AUTOSAR XML (schema 4-2-2)
package /STELLANTIS/EPT/ASWCs
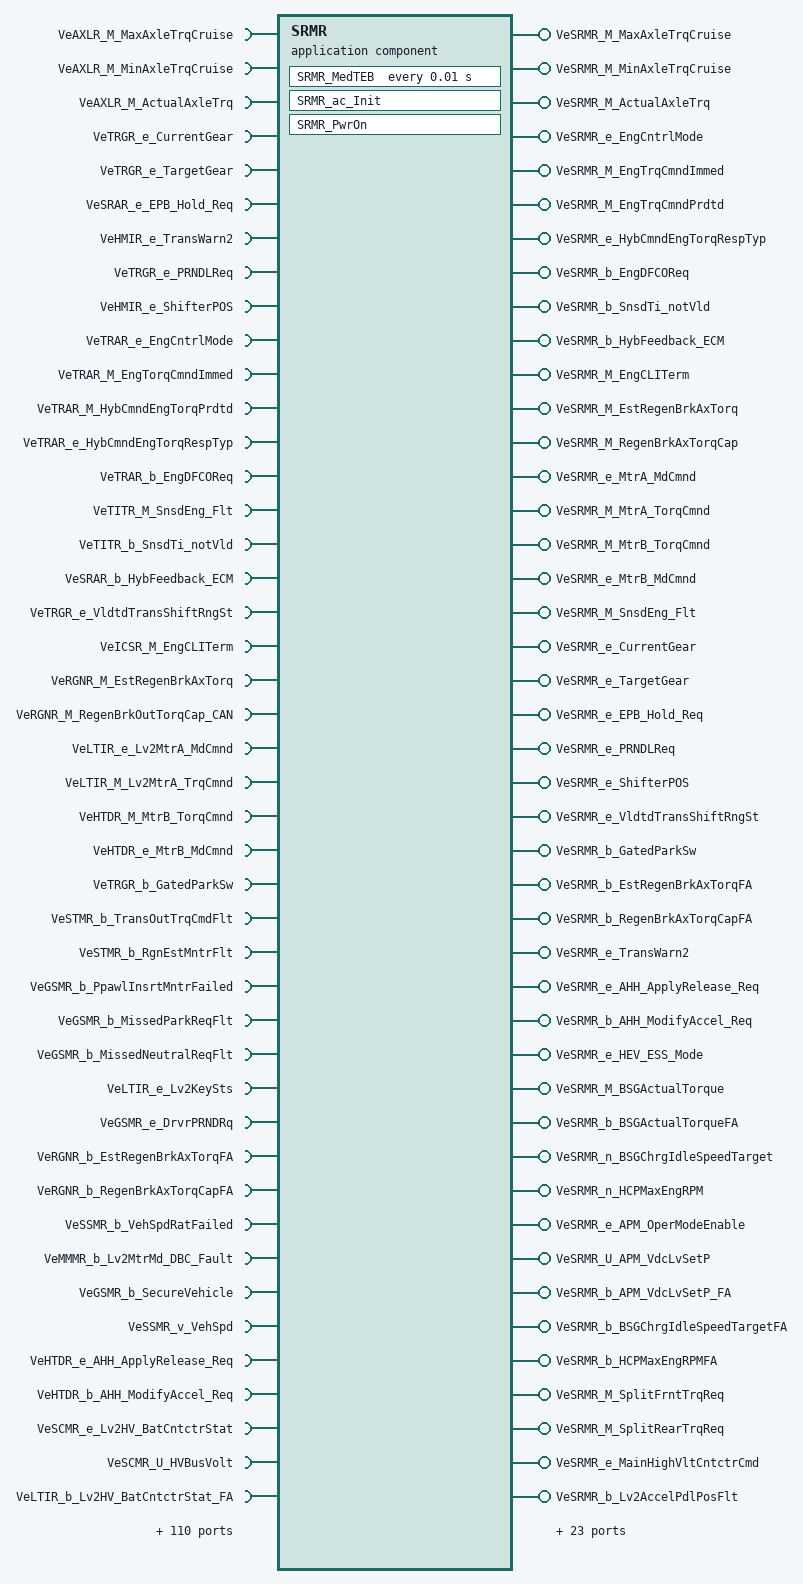
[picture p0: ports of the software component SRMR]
  application sw component type SRMR
    152 x require port:
      VeAXLR_M_MaxAxleTrqCruise: nonqueued-receiver-com-spec{data-element=Value, init-value=0}, required-interface=VeAXLR_M_MaxAxleTrqCruise
      VeAXLR_M_MinAxleTrqCruise: nonqueued-receiver-com-spec{data-element=Value, init-value=0}, required-interface=VeAXLR_M_MinAxleTrqCruise
      VeAXLR_M_ActualAxleTrq: nonqueued-receiver-com-spec{data-element=Value, init-value=0}, required-interface=VeAXLR_M_ActualAxleTrq
      VeTRGR_e_CurrentGear: nonqueued-receiver-com-spec{data-element=Value, init-value=0}, required-interface=VeTRGR_e_CurrentGear
      VeTRGR_e_TargetGear: nonqueued-receiver-com-spec{data-element=Value, init-value=0}, required-interface=VeTRGR_e_TargetGear
      VeSRAR_e_EPB_Hold_Req: nonqueued-receiver-com-spec{data-element=Value, init-value=CeTRGR_e_EPBReq_NA}, required-interface=VeSRAR_e_EPB_Hold_Req
      VeHMIR_e_TransWarn2: nonqueued-receiver-com-spec{data-element=Value, init-value=CeHMIR_e_Warn2_None}, required-interface=VeHMIR_e_TransWarn2
      VeTRGR_e_PRNDLReq: nonqueued-receiver-com-spec{data-element=Value, init-value=0}, required-interface=VeTRGR_e_PRNDLReq
      VeHMIR_e_ShifterPOS: nonqueued-receiver-com-spec{data-element=Value, init-value=CeHMIR_e_ShifterPosNoSelection}, required-interface=VeHMIR_e_ShifterPOS
      VeTRAR_e_EngCntrlMode: nonqueued-receiver-com-spec{data-element=Value, init-value=CeTRAR_e_TorqueMode}, required-interface=VeTRAR_e_EngCntrlMode
      VeTRAR_M_EngTorqCmndImmed: nonqueued-receiver-com-spec{data-element=Value, init-value=0}, required-interface=VeTRAR_M_EngTorqCmndImmed
      VeTRAR_M_HybCmndEngTorqPrdtd: nonqueued-receiver-com-spec{data-element=Value, init-value=0}, required-interface=VeTRAR_M_HybCmndEngTorqPrdtd
      VeTRAR_e_HybCmndEngTorqRespTyp: nonqueued-receiver-com-spec{data-element=Value, init-value=CeTRAR_e_Inactive}, required-interface=VeTRAR_e_HybCmndEngTorqRespTyp
      VeTRAR_b_EngDFCOReq: nonqueued-receiver-com-spec{data-element=Value, init-value=0}, required-interface=VeTRAR_b_EngDFCOReq
      VeTITR_M_SnsdEng_Flt: nonqueued-receiver-com-spec{data-element=Value, init-value=0}, required-interface=VeTITR_M_SnsdEng_Flt
      VeTITR_b_SnsdTi_notVld: nonqueued-receiver-com-spec{data-element=Value, init-value=0}, required-interface=VeTITR_b_SnsdTi_notVld
      VeSRAR_b_HybFeedback_ECM: nonqueued-receiver-com-spec{data-element=Value, init-value=0}, required-interface=VeSRAR_b_HybFeedback_ECM
      VeTRGR_e_VldtdTransShiftRngSt: nonqueued-receiver-com-spec{data-element=Value, init-value=CeTRGR_e_NoSelectionAvailable}, required-interface=VeTRGR_e_VldtdTransShiftRngSt
      VeICSR_M_EngCLITerm: nonqueued-receiver-com-spec{data-element=Value, init-value=0}, required-interface=VeICSR_M_EngCLITerm
      VeRGNR_M_EstRegenBrkAxTorq: nonqueued-receiver-com-spec{data-element=Value, init-value=0}, required-interface=VeRGNR_M_EstRegenBrkAxTorq
      VeRGNR_M_RegenBrkOutTorqCap_CAN: nonqueued-receiver-com-spec{data-element=Value, init-value=0}, required-interface=VeRGNR_M_RegenBrkOutTorqCap_CAN
      VeLTIR_e_Lv2MtrA_MdCmnd: nonqueued-receiver-com-spec{data-element=Value, init-value=CeHTDR_e_DsblNoSwitch}, required-interface=VeLTIR_e_Lv2MtrA_MdCmnd
      VeLTIR_M_Lv2MtrA_TrqCmnd: nonqueued-receiver-com-spec{data-element=Value, init-value=0}, required-interface=VeLTIR_M_Lv2MtrA_TrqCmnd
      VeHTDR_M_MtrB_TorqCmnd: nonqueued-receiver-com-spec{data-element=Value, init-value=0}, required-interface=VeHTDR_M_MtrB_TorqCmnd
      VeHTDR_e_MtrB_MdCmnd: nonqueued-receiver-com-spec{data-element=Value, init-value=CeHTDR_e_DsblNoSwitch}, required-interface=VeHTDR_e_MtrB_MdCmnd
      VeTRGR_b_GatedParkSw: nonqueued-receiver-com-spec{data-element=Value, init-value=0}, required-interface=VeTRGR_b_GatedParkSw
      VeSTMR_b_TransOutTrqCmdFlt: nonqueued-receiver-com-spec{data-element=Value, init-value=0}, required-interface=VeSTMR_b_TransOutTrqCmdFlt
      VeSTMR_b_RgnEstMntrFlt: nonqueued-receiver-com-spec{data-element=Value, init-value=0}, required-interface=VeSTMR_b_RgnEstMntrFlt
      VeGSMR_b_PpawlInsrtMntrFailed: nonqueued-receiver-com-spec{data-element=Value, init-value=0}, required-interface=VeGSMR_b_PpawlInsrtMntrFailed
      VeGSMR_b_MissedParkReqFlt: nonqueued-receiver-com-spec{data-element=Value, init-value=0}, required-interface=VeGSMR_b_MissedParkReqFlt
      VeGSMR_b_MissedNeutralReqFlt: nonqueued-receiver-com-spec{data-element=Value, init-value=0}, required-interface=VeGSMR_b_MissedNeutralReqFlt
      VeLTIR_e_Lv2KeySts: nonqueued-receiver-com-spec{data-element=Value, init-value=CeLTIR_e_IGN_LK}, required-interface=VeLTIR_e_Lv2KeySts
      VeGSMR_e_DrvrPRNDRq: nonqueued-receiver-com-spec{data-element=Value, init-value=CeGSMR_e_PRNDInit}, required-interface=VeGSMR_e_DrvrPRNDRq
      VeRGNR_b_EstRegenBrkAxTorqFA: nonqueued-receiver-com-spec{data-element=Value, init-value=0}, required-interface=VeRGNR_b_EstRegenBrkAxTorqFA
      VeRGNR_b_RegenBrkAxTorqCapFA: nonqueued-receiver-com-spec{data-element=Value, init-value=0}, required-interface=VeRGNR_b_RegenBrkAxTorqCapFA
      VeSSMR_b_VehSpdRatFailed: nonqueued-receiver-com-spec{data-element=Value, init-value=0}, required-interface=VeSSMR_b_VehSpdRatFailed
      VeMMMR_b_Lv2MtrMd_DBC_Fault: nonqueued-receiver-com-spec{data-element=Value, init-value=0}, required-interface=VeMMMR_b_Lv2MtrMd_DBC_Fault
      VeGSMR_b_SecureVehicle: nonqueued-receiver-com-spec{data-element=Value, init-value=0}, required-interface=VeGSMR_b_SecureVehicle
      VeSSMR_v_VehSpd: nonqueued-receiver-com-spec{data-element=Value, init-value=0}, required-interface=VeSSMR_v_VehSpd
      VeHTDR_e_AHH_ApplyRelease_Req: nonqueued-receiver-com-spec{data-element=Value, init-value=CeHTDR_e_AHH_Inactive}, required-interface=VeHTDR_e_AHH_ApplyRelease_Req
      VeHTDR_b_AHH_ModifyAccel_Req: nonqueued-receiver-com-spec{data-element=Value, init-value=0}, required-interface=VeHTDR_b_AHH_ModifyAccel_Req
      VeSCMR_e_Lv2HV_BatCntctrStat: nonqueued-receiver-com-spec{data-element=Value, init-value=0}, required-interface=VeSCMR_e_Lv2HV_BatCntctrStat
      VeSCMR_U_HVBusVolt: nonqueued-receiver-com-spec{data-element=Value, init-value=0}, required-interface=VeSCMR_U_HVBusVolt
      VeLTIR_b_Lv2HV_BatCntctrStat_FA: nonqueued-receiver-com-spec{data-element=Value, init-value=0}, required-interface=VeLTIR_b_Lv2HV_BatCntctrStat_FA
      VeSTMR_b_UnIntendedVehMovInNeutral: nonqueued-receiver-com-spec{data-element=Value, init-value=0}, required-interface=VeSTMR_b_UnIntendedVehMovInNeutral
      VeGSMR_b_ApplyEPB: nonqueued-receiver-com-spec{data-element=Value, init-value=0}, required-interface=VeGSMR_b_ApplyEPB
      VeASMR_e_Lv2EngStrtStpMd: nonqueued-receiver-com-spec{data-element=Value, init-value=0}, required-interface=VeASMR_e_Lv2EngStrtStpMd
      VeMTIR_M_MtrA_TorqAchieved: nonqueued-receiver-com-spec{data-element=Value, init-value=0}, required-interface=VeMTIR_M_MtrA_TorqAchieved
      VeMTIR_b_MtrA_TorqAchievedFA: nonqueued-receiver-com-spec{data-element=Value, init-value=0}, required-interface=VeMTIR_b_MtrA_TorqAchievedFA
      VeOHSR_n_IdleSpeed_Target: nonqueued-receiver-com-spec{data-element=Value, init-value=0}, required-interface=VeOHSR_n_IdleSpeed_Target
      VeSRAR_n_HCPMaxEngRPM: nonqueued-receiver-com-spec{data-element=Value, init-value=0}, required-interface=VeSRAR_n_HCPMaxEngRPM
      VeGENR_e_stModeReq: nonqueued-receiver-com-spec{data-element=Value, init-value=CeGENR_e_Default}, required-interface=VeGENR_e_stModeReq
      VeGENR_U_SetPVoltRq: nonqueued-receiver-com-spec{data-element=Value, init-value=0}, required-interface=VeGENR_U_SetPVoltRq
      VeGENR_b_SetPVoltRqFA: nonqueued-receiver-com-spec{data-element=Value, init-value=0}, required-interface=VeGENR_b_SetPVoltRqFA
      VeSCMR_M_Lv2MtrA_TrqAchieved: nonqueued-receiver-com-spec{data-element=Value, init-value=0}, required-interface=VeSCMR_M_Lv2MtrA_TrqAchieved
      VeLTIR_b_Lv2MtrA_TrqAchieved_FA: nonqueued-receiver-com-spec{data-element=Value, init-value=0}, required-interface=VeLTIR_b_Lv2MtrA_TrqAchieved_FA
      VeSCMR_Pct_Lv2HV_BatSOC: nonqueued-receiver-com-spec{data-element=Value, init-value=0}, required-interface=VeSCMR_Pct_Lv2HV_BatSOC
      VeLTIR_b_Lv2HV_BatSOC_FA: nonqueued-receiver-com-spec{data-element=Value, init-value=0}, required-interface=VeLTIR_b_Lv2HV_BatSOC_FA
      VeASMR_b_Lv2AutoStrtFA: nonqueued-receiver-com-spec{data-element=Value, init-value=0}, required-interface=VeASMR_b_Lv2AutoStrtFA
      VeASMR_b_Lv2AutoStpFA: nonqueued-receiver-com-spec{data-element=Value, init-value=0}, required-interface=VeASMR_b_Lv2AutoStpFA
      VeSTMR_b_EngTorqCmndMntrFlt: nonqueued-receiver-com-spec{data-element=Value, init-value=0}, required-interface=VeSTMR_b_EngTorqCmndMntrFlt
      VeSCMR_b_Lv2EVRDesVSetP_FA: nonqueued-receiver-com-spec{data-element=Value, init-value=0}, required-interface=VeSCMR_b_Lv2EVRDesVSetP_FA
      VeSCMR_U_Lv2EVRDesVSetP: nonqueued-receiver-com-spec{data-element=Value, init-value=0}, required-interface=VeSCMR_U_Lv2EVRDesVSetP
      VeGSMR_b_PpawlInsrtFailed: nonqueued-receiver-com-spec{data-element=Value, init-value=0}, required-interface=VeGSMR_b_PpawlInsrtFailed
      VeSTMR_b_OutTrq_MaxLimFail: nonqueued-receiver-com-spec{data-element=Value, init-value=0}, required-interface=VeSTMR_b_OutTrq_MaxLimFail
      VeAXLR_M_FrntAxlTrqEst: nonqueued-receiver-com-spec{data-element=Value, init-value=0}, required-interface=VeAXLR_M_FrntAxlTrqEst
      VeAXLR_M_RrAxlTrqEst: nonqueued-receiver-com-spec{data-element=Value, init-value=0}, required-interface=VeAXLR_M_RrAxlTrqEst
      VeSTMR_b_OutTrq_MinLimFail: nonqueued-receiver-com-spec{data-element=Value, init-value=0}, required-interface=VeSTMR_b_OutTrq_MinLimFail
      VeSTMR_b_P4TrqMntrFlt: nonqueued-receiver-com-spec{data-element=Value, init-value=0}, required-interface=VeSTMR_b_P4TrqMntrFlt
      VeESSR_e_EngStrtStpMd: nonqueued-receiver-com-spec{data-element=Value, init-value=CeESSR_e_Stop}, required-interface=VeESSR_e_EngStrtStpMd
      VeASMR_n_Lv2EngSpd: nonqueued-receiver-com-spec{data-element=Value, init-value=0}, required-interface=VeASMR_n_Lv2EngSpd
      VeSCMR_e_Lv2ESS_EngStateEE: nonqueued-receiver-com-spec{data-element=Value, init-value=0}, required-interface=VeSCMR_e_Lv2ESS_EngStateEE
      VeSCMR_b_SharedMemFlt: nonqueued-receiver-com-spec{data-element=Value, init-value=0}, required-interface=VeSCMR_b_SharedMemFlt
      VeSCMR_e_Lv2MtrA_InvrtrSts: nonqueued-receiver-com-spec{data-element=Value, init-value=0}, required-interface=VeSCMR_e_Lv2MtrA_InvrtrSts
      VeSCMR_b_Lv2HV_BatCntctrOpn: nonqueued-receiver-com-spec{data-element=Value, init-value=0}, required-interface=VeSCMR_b_Lv2HV_BatCntctrOpn
      VeSCMR_T_Lv2HV_BatModTempMax: nonqueued-receiver-com-spec{data-element=Value, init-value=0}, required-interface=VeSCMR_T_Lv2HV_BatModTempMax
      VeLTIR_b_Lv2HV_BatModTempMax_FA: nonqueued-receiver-com-spec{data-element=Value, init-value=0}, required-interface=VeLTIR_b_Lv2HV_BatModTempMax_FA
      VeLTIR_b_Lv2APM_HVBatVlt_FA: nonqueued-receiver-com-spec{data-element=Value, init-value=0}, required-interface=VeLTIR_b_Lv2APM_HVBatVlt_FA
      VeSCMR_b_BPCM_HVBatVltFA: nonqueued-receiver-com-spec{data-element=Value, init-value=0}, required-interface=VeSCMR_b_BPCM_HVBatVltFA
      VeSCMR_U_InvrtrA_HVBatVlt: nonqueued-receiver-com-spec{data-element=Value, init-value=0}, required-interface=VeSCMR_U_InvrtrA_HVBatVlt
      VeSCMR_U_BPCM_HVBatVlt: nonqueued-receiver-com-spec{data-element=Value, init-value=0}, required-interface=VeSCMR_U_BPCM_HVBatVlt
      VeSCMR_U_Lv2APM_HVBatVlt: nonqueued-receiver-com-spec{data-element=Value, init-value=0}, required-interface=VeSCMR_U_Lv2APM_HVBatVlt
      VeSCMR_e_Lv2APM_FailureType: nonqueued-receiver-com-spec{data-element=Value, init-value=0}, required-interface=VeSCMR_e_Lv2APM_FailureType
      VeSCMR_e_Lv2APM_FailureReason: nonqueued-receiver-com-spec{data-element=Value, init-value=0}, required-interface=VeSCMR_e_Lv2APM_FailureReason
      VeSCMR_b_Lv2HV_BatCntctrReq: nonqueued-receiver-com-spec{data-element=Value, init-value=0}, required-interface=VeSCMR_b_Lv2HV_BatCntctrReq
      VeHPMR_e_HighVltCntctrCntrl: nonqueued-receiver-com-spec{data-element=Value, init-value=CeHPMR_e_Open}, required-interface=VeHPMR_e_HighVltCntctrCntrl
      VePSMR_b_Lv2AccelPdlPosFlt: nonqueued-receiver-com-spec{data-element=Value, init-value=0}, required-interface=VePSMR_b_Lv2AccelPdlPosFlt
      VeLTIR_b_Lv2KeySts_FA: nonqueued-receiver-com-spec{data-element=Value, init-value=0}, required-interface=VeLTIR_b_Lv2KeySts_FA
      VeSCMR_b_ASC_Req: nonqueued-receiver-com-spec{data-element=Value, init-value=0}, required-interface=VeSCMR_b_ASC_Req
      VeSTMR_b_Allow_OpenBattCntctr: nonqueued-receiver-com-spec{data-element=Value, init-value=0}, required-interface=VeSTMR_b_Allow_OpenBattCntctr
      VeSTMR_b_P1fEstMntrFlt: nonqueued-receiver-com-spec{data-element=Value, init-value=0}, required-interface=VeSTMR_b_P1fEstMntrFlt
      VeSRAR_b_Popup_Msg15: nonqueued-receiver-com-spec{data-element=Value, init-value=0}, required-interface=VeSRAR_b_Popup_Msg15
      VeDTMR_b_Lv2_OPD_ON_FA: nonqueued-receiver-com-spec{data-element=Value, init-value=0}, required-interface=VeDTMR_b_Lv2_OPD_ON_FA
      VeSRAR_b_Popup_Msg9: nonqueued-receiver-com-spec{data-element=Value, init-value=0}, required-interface=VeSRAR_b_Popup_Msg9
      VeRGNR_b_AeCoastTorqDiffActv: nonqueued-receiver-com-spec{data-element=Value, init-value=0}, required-interface=VeRGNR_b_AeCoastTorqDiffActv
      VeDTRR_b_VehStndStillReq_OPD: nonqueued-receiver-com-spec{data-element=Value, init-value=0}, required-interface=VeDTRR_b_VehStndStillReq_OPD
      VeRGNR_M_AeCoastTorqDiff: nonqueued-receiver-com-spec{data-element=Value, init-value=0}, required-interface=VeRGNR_M_AeCoastTorqDiff
      VeSTMR_b_Lv2BattWeldFA: nonqueued-receiver-com-spec{data-element=Value, init-value=0}, required-interface=VeSTMR_b_Lv2BattWeldFA
      VeSTMR_b_P1fNotGeneratorMode: nonqueued-receiver-com-spec{data-element=Value, init-value=0}, required-interface=VeSTMR_b_P1fNotGeneratorMode
      VeSTMR_b_FrontAxleTrqEstMntrFlt: nonqueued-receiver-com-spec{data-element=Value, init-value=0}, required-interface=VeSTMR_b_FrontAxleTrqEstMntrFlt
      VeAXLR_b_ActualAxleTrqFA: nonqueued-receiver-com-spec{data-element=Value, init-value=0}, required-interface=VeAXLR_b_ActualAxleTrqFA
      VeSCMR_e_MSSBEV_Action: nonqueued-receiver-com-spec{data-element=Value, init-value=0}, required-interface=VeSCMR_e_MSSBEV_Action
      VeLTIR_e_Lv2BrkPdlStat: nonqueued-receiver-com-spec{data-element=Value, init-value=0}, required-interface=VeLTIR_e_Lv2BrkPdlStat
      VeLTIR_M_Lv2BrkTrq: nonqueued-receiver-com-spec{data-element=Value, init-value=0}, required-interface=VeLTIR_M_Lv2BrkTrq
      VePSMR_Pct_Lv2AccelPdlPos: nonqueued-receiver-com-spec{data-element=Value, init-value=0}, required-interface=VePSMR_Pct_Lv2AccelPdlPos
      VeSSMR_b_VehSpdFA: nonqueued-receiver-com-spec{data-element=Value, init-value=0}, required-interface=VeSSMR_b_VehSpdFA
      VeDTRR_b_DrvrIntndedAxleTrqRawFA: nonqueued-receiver-com-spec{data-element=Value, init-value=0}, required-interface=VeDTRR_b_DrvrIntndedAxleTrqRawFA
      VeAXLR_M_DrvrIntndedAxleTrq_Arb: nonqueued-receiver-com-spec{data-element=Value, init-value=0}, required-interface=VeAXLR_M_DrvrIntndedAxleTrq_Arb
      VeSTMR_b_FrntAxlTrqEstFA: nonqueued-receiver-com-spec{data-element=Value, init-value=0}, required-interface=VeSTMR_b_FrntAxlTrqEstFA
      VeSTMR_b_RrAxlTrqEstFA: nonqueued-receiver-com-spec{data-element=Value, init-value=0}, required-interface=VeSTMR_b_RrAxlTrqEstFA
      VeSTMR_b_DrvrIntndedAxleTrqFA: nonqueued-receiver-com-spec{data-element=Value, init-value=0}, required-interface=VeSTMR_b_DrvrIntndedAxleTrqFA
      VeSCMR_e_MSSBEV_HVEM_TargetSts: nonqueued-receiver-com-spec{data-element=Value, init-value=0}, required-interface=VeSCMR_e_MSSBEV_HVEM_TargetSts
      VeEMMR_b_Lv2APMStMode_FA: nonqueued-receiver-com-spec{data-element=Value, init-value=0}, required-interface=VeEMMR_b_Lv2APMStMode_FA
      VeSCMR_M_Lv2MtrB_MaxTrq: nonqueued-receiver-com-spec{data-element=Value, init-value=0}, required-interface=VeSCMR_M_Lv2MtrB_MaxTrq
      VeLTIR_b_Lv2MtrB_MaxTrq_FA: nonqueued-receiver-com-spec{data-element=Value, init-value=0}, required-interface=VeLTIR_b_Lv2MtrB_MaxTrq_FA
      VeSCMR_M_Lv2MtrB_MinTrq: nonqueued-receiver-com-spec{data-element=Value, init-value=0}, required-interface=VeSCMR_M_Lv2MtrB_MinTrq
      VeLTIR_b_Lv2MtrB_MinTrq_FA: nonqueued-receiver-com-spec{data-element=Value, init-value=0}, required-interface=VeLTIR_b_Lv2MtrB_MinTrq_FA
      VeSCMR_M_Lv2MtrA_MaxTrq: nonqueued-receiver-com-spec{data-element=Value, init-value=0}, required-interface=VeSCMR_M_Lv2MtrA_MaxTrq
      VeLTIR_b_Lv2MtrA_MaxTrq_FA: nonqueued-receiver-com-spec{data-element=Value, init-value=0}, required-interface=VeLTIR_b_Lv2MtrA_MaxTrq_FA
      VeSCMR_M_Lv2MtrA_MinTrq: nonqueued-receiver-com-spec{data-element=Value, init-value=0}, required-interface=VeSCMR_M_Lv2MtrA_MinTrq
      VeLTIR_b_Lv2MtrA_MinTrq_FA: nonqueued-receiver-com-spec{data-element=Value, init-value=0}, required-interface=VeLTIR_b_Lv2MtrA_MinTrq_FA
      VeSCMR_b_MSSBEV_Vbatt_mV_UV: nonqueued-receiver-com-spec{data-element=Value, init-value=0}, required-interface=VeSCMR_b_MSSBEV_Vbatt_mV_UV
      VeGENR_b_SrvcBattReChrgFlSts: nonqueued-receiver-com-spec{data-element=Value, init-value=0}, required-interface=VeGENR_b_SrvcBattReChrgFlSts
      VeLTIR_b_Lv2BrkPdlStatFlt: nonqueued-receiver-com-spec{data-element=Value, init-value=0}, required-interface=VeLTIR_b_Lv2BrkPdlStatFlt
      VeLTIR_b_Lv2BrkTrqFlt: nonqueued-receiver-com-spec{data-element=Value, init-value=0}, required-interface=VeLTIR_b_Lv2BrkTrqFlt
      VeSSMR_n_MtrBSpd: nonqueued-receiver-com-spec{data-element=Value, init-value=0}, required-interface=VeSSMR_n_MtrBSpd
      VeDTMR_b_DTRcmdFlt: nonqueued-receiver-com-spec{data-element=Value, init-value=0}, required-interface=VeDTMR_b_DTRcmdFlt
      VeSTMR_b_TrqSplit_OS_US: nonqueued-receiver-com-spec{data-element=Value, init-value=0}, required-interface=VeSTMR_b_TrqSplit_OS_US
      VeCANR_e_CanLocEnblStatus: nonqueued-receiver-com-spec{data-element=VeCANR_e_CanLocEnblStatus, init-value=CePWMD_e_LOC_Disable}, required-interface=VeCANR_e_CanLocEnblStatus
      VeSABR_b_SL2outBEV_VDAB_eAWD_SafActive: nonqueued-receiver-com-spec{data-element=Value, init-value=0}, required-interface=VeSABR_b_SL2outBEV_VDAB_eAWD_SafActive
      VeSABR_b_SL2outBEV_VDAB_WED_SafActive: nonqueued-receiver-com-spec{data-element=Value, init-value=0}, required-interface=VeSABR_b_SL2outBEV_VDAB_WED_SafActive
      VeSABR_b_SL2outBEV_VDAB_eLOCK_SafActive: nonqueued-receiver-com-spec{data-element=Value, init-value=0}, required-interface=VeSABR_b_SL2outBEV_VDAB_eLOCK_SafActive
      VeSABR_b_SL2outBEV_VDAB_eLSD_SafActive: nonqueued-receiver-com-spec{data-element=Value, init-value=0}, required-interface=VeSABR_b_SL2outBEV_VDAB_eLSD_SafActive
      VeGRAR_e_MSSBEV_Action: nonqueued-receiver-com-spec{data-element=Value, init-value=CeGRAR_e_NoLimitation}, required-interface=VeGRAR_e_MSSBEV_Action
      VeHPMR_b_MtrSystemActive: nonqueued-receiver-com-spec{data-element=Value, init-value=0}, required-interface=VeHPMR_b_MtrSystemActive
      VeGRAR_b_EngageParkBrk: nonqueued-receiver-com-spec{data-element=Value, init-value=0}, required-interface=VeGRAR_b_EngageParkBrk
      VeGRAR_b_DisableECoast: nonqueued-receiver-com-spec{data-element=Value, init-value=0}, required-interface=VeGRAR_b_DisableECoast
      VeGRAR_b_DisableOPD: nonqueued-receiver-com-spec{data-element=Value, init-value=0}, required-interface=VeGRAR_b_DisableOPD
      VePPCR_e_PPawl_HW_Request: nonqueued-receiver-com-spec{data-element=Value, init-value=CePPCR_e_Req_No_Req}, required-interface=VePPCR_e_PPawl_HW_Request
      VeSCMR_b_Lv2MtrAFlt_HV_CntctrOpnRq: nonqueued-receiver-com-spec{data-element=Value, init-value=0}, required-interface=VeSCMR_b_Lv2MtrAFlt_HV_CntctrOpnRq
      VeSCMR_b_Lv2MtrBFlt_HV_CntctrOpnRq: nonqueued-receiver-com-spec{data-element=Value, init-value=0}, required-interface=VeSCMR_b_Lv2MtrBFlt_HV_CntctrOpnRq
      VeGRAR_e_TotMtrTrqRmdlActn: nonqueued-receiver-com-spec{data-element=Value, init-value=CeGRAR_e_Normal}, required-interface=VeGRAR_e_TotMtrTrqRmdlActn
      VeGRAR_b_TotMtrTrqIncRampEnbl: nonqueued-receiver-com-spec{data-element=Value, init-value=0}, required-interface=VeGRAR_b_TotMtrTrqIncRampEnbl
      VeGRAR_b_Assign_RA_RIP_Ratio: nonqueued-receiver-com-spec{data-element=Value, init-value=0}, required-interface=VeGRAR_b_Assign_RA_RIP_Ratio
      VeGRAR_r_RA_RIP_Ratio: nonqueued-receiver-com-spec{data-element=Value, init-value=0}, required-interface=VeGRAR_r_RA_RIP_Ratio
      VeSCMR_b_Lv2MtrCFlt_HV_CntctrOpnRq: nonqueued-receiver-com-spec{data-element=Value, init-value=0}, required-interface=VeSCMR_b_Lv2MtrCFlt_HV_CntctrOpnRq
      VeRGNR_M_RegenBrkOutTorqCap_Frnt: nonqueued-receiver-com-spec{data-element=Value, init-value=0}, required-interface=VeRGNR_M_RegenBrkOutTorqCap_Frnt
      VeRGNR_M_RegenBrkOutTorqCap_Rear: nonqueued-receiver-com-spec{data-element=Value, init-value=0}, required-interface=VeRGNR_M_RegenBrkOutTorqCap_Rear
      VeGRAR_b_DisableRegenBrkTrq: nonqueued-receiver-com-spec{data-element=Value, init-value=0}, required-interface=VeGRAR_b_DisableRegenBrkTrq
      VePSMR_e_Lv2PVSMode: nonqueued-receiver-com-spec{data-element=Value, init-value=CePSMR_e_NO_Fault}, required-interface=VePSMR_e_Lv2PVSMode
      VeGRAR_e_ParkPawlReq: nonqueued-receiver-com-spec{data-element=Value, init-value=CeGRAR_e_PP_Normal}, required-interface=VeGRAR_e_ParkPawlReq
      VeGRAR_e_PRND_Req: nonqueued-receiver-com-spec{data-element=Value, init-value=CeGRAR_e_PRND_Normal}, required-interface=VeGRAR_e_PRND_Req
    67 x provide port:
      VeSRMR_M_MaxAxleTrqCruise: nonqueued-sender-com-spec{data-element=Value, init-value=0}, provided-interface=VeSRMR_M_MaxAxleTrqCruise
      VeSRMR_M_MinAxleTrqCruise: nonqueued-sender-com-spec{data-element=Value, init-value=0}, provided-interface=VeSRMR_M_MinAxleTrqCruise
      VeSRMR_M_ActualAxleTrq: nonqueued-sender-com-spec{data-element=Value, init-value=0}, provided-interface=VeSRMR_M_ActualAxleTrq
      VeSRMR_e_EngCntrlMode: nonqueued-sender-com-spec{data-element=Value, init-value=0}, provided-interface=VeSRMR_e_EngCntrlMode
      VeSRMR_M_EngTrqCmndImmed: nonqueued-sender-com-spec{data-element=Value, init-value=0}, provided-interface=VeSRMR_M_EngTrqCmndImmed
      VeSRMR_M_EngTrqCmndPrdtd: nonqueued-sender-com-spec{data-element=Value, init-value=0}, provided-interface=VeSRMR_M_EngTrqCmndPrdtd
      VeSRMR_e_HybCmndEngTorqRespTyp: nonqueued-sender-com-spec{data-element=Value, init-value=0}, provided-interface=VeSRMR_e_HybCmndEngTorqRespTyp
      VeSRMR_b_EngDFCOReq: nonqueued-sender-com-spec{data-element=Value, init-value=0}, provided-interface=VeSRMR_b_EngDFCOReq
      VeSRMR_b_SnsdTi_notVld: nonqueued-sender-com-spec{data-element=Value, init-value=0}, provided-interface=VeSRMR_b_SnsdTi_notVld
      VeSRMR_b_HybFeedback_ECM: nonqueued-sender-com-spec{data-element=Value, init-value=0}, provided-interface=VeSRMR_b_HybFeedback_ECM
      VeSRMR_M_EngCLITerm: nonqueued-sender-com-spec{data-element=Value, init-value=0}, provided-interface=VeSRMR_M_EngCLITerm
      VeSRMR_M_EstRegenBrkAxTorq: nonqueued-sender-com-spec{data-element=Value, init-value=0}, provided-interface=VeSRMR_M_EstRegenBrkAxTorq
      VeSRMR_M_RegenBrkAxTorqCap: nonqueued-sender-com-spec{data-element=Value, init-value=0}, provided-interface=VeSRMR_M_RegenBrkAxTorqCap
      VeSRMR_e_MtrA_MdCmnd: nonqueued-sender-com-spec{data-element=Value, init-value=CeHTDR_e_DsblNoSwitch}, provided-interface=VeSRMR_e_MtrA_MdCmnd
      VeSRMR_M_MtrA_TorqCmnd: nonqueued-sender-com-spec{data-element=Value, init-value=0}, provided-interface=VeSRMR_M_MtrA_TorqCmnd
      VeSRMR_M_MtrB_TorqCmnd: nonqueued-sender-com-spec{data-element=Value, init-value=0}, provided-interface=VeSRMR_M_MtrB_TorqCmnd
      VeSRMR_e_MtrB_MdCmnd: nonqueued-sender-com-spec{data-element=Value, init-value=CeHTDR_e_DsblNoSwitch}, provided-interface=VeSRMR_e_MtrB_MdCmnd
      VeSRMR_M_SnsdEng_Flt: nonqueued-sender-com-spec{data-element=Value, init-value=0}, provided-interface=VeSRMR_M_SnsdEng_Flt
      VeSRMR_e_CurrentGear: nonqueued-sender-com-spec{data-element=Value, init-value=0}, provided-interface=VeSRMR_e_CurrentGear
      VeSRMR_e_TargetGear: nonqueued-sender-com-spec{data-element=Value, init-value=0}, provided-interface=VeSRMR_e_TargetGear
      VeSRMR_e_EPB_Hold_Req: nonqueued-sender-com-spec{data-element=Value, init-value=0}, provided-interface=VeSRMR_e_EPB_Hold_Req
      VeSRMR_e_PRNDLReq: nonqueued-sender-com-spec{data-element=Value, init-value=0}, provided-interface=VeSRMR_e_PRNDLReq
      VeSRMR_e_ShifterPOS: nonqueued-sender-com-spec{data-element=Value, init-value=0}, provided-interface=VeSRMR_e_ShifterPOS
      VeSRMR_e_VldtdTransShiftRngSt: nonqueued-sender-com-spec{data-element=Value, init-value=CeTRGR_e_NoSelectionAvailable}, provided-interface=VeSRMR_e_VldtdTransShiftRngSt
      VeSRMR_b_GatedParkSw: nonqueued-sender-com-spec{data-element=Value, init-value=0}, provided-interface=VeSRMR_b_GatedParkSw
      VeSRMR_b_EstRegenBrkAxTorqFA: nonqueued-sender-com-spec{data-element=Value, init-value=0}, provided-interface=VeSRMR_b_EstRegenBrkAxTorqFA
      VeSRMR_b_RegenBrkAxTorqCapFA: nonqueued-sender-com-spec{data-element=Value, init-value=0}, provided-interface=VeSRMR_b_RegenBrkAxTorqCapFA
      VeSRMR_e_TransWarn2: nonqueued-sender-com-spec{data-element=Value, init-value=0}, provided-interface=VeSRMR_e_TransWarn2
      VeSRMR_e_AHH_ApplyRelease_Req: nonqueued-sender-com-spec{data-element=Value, init-value=0}, provided-interface=VeSRMR_e_AHH_ApplyRelease_Req
      VeSRMR_b_AHH_ModifyAccel_Req: nonqueued-sender-com-spec{data-element=Value, init-value=0}, provided-interface=VeSRMR_b_AHH_ModifyAccel_Req
      VeSRMR_e_HEV_ESS_Mode: nonqueued-sender-com-spec{data-element=Value, init-value=0}, provided-interface=VeSRMR_e_HEV_ESS_Mode
      VeSRMR_M_BSGActualTorque: nonqueued-sender-com-spec{data-element=Value, init-value=0}, provided-interface=VeSRMR_M_BSGActualTorque
      VeSRMR_b_BSGActualTorqueFA: nonqueued-sender-com-spec{data-element=Value, init-value=0}, provided-interface=VeSRMR_b_BSGActualTorqueFA
      VeSRMR_n_BSGChrgIdleSpeedTarget: nonqueued-sender-com-spec{data-element=Value, init-value=0}, provided-interface=VeSRMR_n_BSGChrgIdleSpeedTarget
      VeSRMR_n_HCPMaxEngRPM: nonqueued-sender-com-spec{data-element=Value, init-value=0}, provided-interface=VeSRMR_n_HCPMaxEngRPM
      VeSRMR_e_APM_OperModeEnable: nonqueued-sender-com-spec{data-element=Value, init-value=0}, provided-interface=VeSRMR_e_APM_OperModeEnable
      VeSRMR_U_APM_VdcLvSetP: nonqueued-sender-com-spec{data-element=Value, init-value=0}, provided-interface=VeSRMR_U_APM_VdcLvSetP
      VeSRMR_b_APM_VdcLvSetP_FA: nonqueued-sender-com-spec{data-element=Value, init-value=0}, provided-interface=VeSRMR_b_APM_VdcLvSetP_FA
      VeSRMR_b_BSGChrgIdleSpeedTargetFA: nonqueued-sender-com-spec{data-element=Value, init-value=0}, provided-interface=VeSRMR_b_BSGChrgIdleSpeedTargetFA
      VeSRMR_b_HCPMaxEngRPMFA: nonqueued-sender-com-spec{data-element=Value, init-value=0}, provided-interface=VeSRMR_b_HCPMaxEngRPMFA
      VeSRMR_M_SplitFrntTrqReq: nonqueued-sender-com-spec{data-element=Value, init-value=0}, provided-interface=VeSRMR_M_SplitFrntTrqReq
      VeSRMR_M_SplitRearTrqReq: nonqueued-sender-com-spec{data-element=Value, init-value=0}, provided-interface=VeSRMR_M_SplitRearTrqReq
      VeSRMR_e_MainHighVltCntctrCmd: nonqueued-sender-com-spec{data-element=Value, init-value=0}, provided-interface=VeSRMR_e_MainHighVltCntctrCmd
      VeSRMR_b_Lv2AccelPdlPosFlt: nonqueued-sender-com-spec{data-element=Value, init-value=0}, provided-interface=VeSRMR_b_Lv2AccelPdlPosFlt
      VeSRMR_Pct_Lv2AccelPdlPos: nonqueued-sender-com-spec{data-element=Value, init-value=0}, provided-interface=VeSRMR_Pct_Lv2AccelPdlPos
      VeSRMR_b_Popup_Msg15: nonqueued-sender-com-spec{data-element=Value, init-value=0}, provided-interface=VeSRMR_b_Popup_Msg15
      VeSRMR_b_Popup_Msg9: nonqueued-sender-com-spec{data-element=Value, init-value=0}, provided-interface=VeSRMR_b_Popup_Msg9
      VeSRMR_b_AeCoastTorqDiffActv: nonqueued-sender-com-spec{data-element=Value, init-value=0}, provided-interface=VeSRMR_b_AeCoastTorqDiffActv
      VeSRMR_M_AeCoastTorqDiff: nonqueued-sender-com-spec{data-element=Value, init-value=0}, provided-interface=VeSRMR_M_AeCoastTorqDiff
      VeSRMR_b_VehStndStillReq_OPD: nonqueued-sender-com-spec{data-element=Value, init-value=0}, provided-interface=VeSRMR_b_VehStndStillReq_OPD
      VeSRMR_b_ActualAxleTrqFA: nonqueued-sender-com-spec{data-element=Value, init-value=0}, provided-interface=VeSRMR_b_ActualAxleTrqFA
      VeSRMR_M_DrvrIntndedAxleTrq: nonqueued-sender-com-spec{data-element=Value, init-value=0}, provided-interface=VeSRMR_M_DrvrIntndedAxleTrq
      VeSRMR_b_DrvrIntndedAxleTrqFA: nonqueued-sender-com-spec{data-element=Value, init-value=0}, provided-interface=VeSRMR_b_DrvrIntndedAxleTrqFA
      VeSRMR_e_stModeReq: nonqueued-sender-com-spec{data-element=Value, init-value=0}, provided-interface=VeSRMR_e_stModeReq
      VeSRMR_b_CrashDischarge: nonqueued-sender-com-spec{data-element=Value, init-value=0}, provided-interface=VeSRMR_b_CrashDischarge
      VeSRMR_b_SrvcBattReChrgFlSts: nonqueued-sender-com-spec{data-element=Value, init-value=0}, provided-interface=VeSRMR_b_SrvcBattReChrgFlSts
      VeSRMR_e_GRAR_eAWD_TargetSts: nonqueued-sender-com-spec{data-element=Value, init-value=CeSRMR_e_TargetSts_DiagOff}, provided-interface=VeSRMR_e_GRAR_eAWD_TargetSts
      VeSRMR_e_GRAR_WED_TargetSts: nonqueued-sender-com-spec{data-element=Value, init-value=CeSRMR_e_TargetSts_DiagOff}, provided-interface=VeSRMR_e_GRAR_WED_TargetSts
      VeSRMR_e_GRAR_eLOCK_TargetSts: nonqueued-sender-com-spec{data-element=Value, init-value=CeSRMR_e_TargetSts_DiagOff}, provided-interface=VeSRMR_e_GRAR_eLOCK_TargetSts
      VeSRMR_e_GRAR_eLSD_TargetSts: nonqueued-sender-com-spec{data-element=Value, init-value=CeSRMR_e_TargetSts_DiagOff}, provided-interface=VeSRMR_e_GRAR_eLSD_TargetSts
      VeSRMR_e_LimitationMd: nonqueued-sender-com-spec{data-element=Value, init-value=CeSRMR_e_NoLimitation}, provided-interface=VeSRMR_e_LimitationMd
      VeSRMR_b_MtrMdVldtnFltErr: nonqueued-sender-com-spec{data-element=Value, init-value=0}, provided-interface=VeSRMR_b_MtrMdVldtnFltErr
      VeSRMR_v_VehSpd: nonqueued-sender-com-spec{data-element=Value, init-value=0}, provided-interface=VeSRMR_v_VehSpd
      VeSRMR_b_VehSpdFA: nonqueued-sender-com-spec{data-element=Value, init-value=0}, provided-interface=VeSRMR_b_VehSpdFA
      VeSRMR_e_PPawl_Request: nonqueued-sender-com-spec{data-element=Value, init-value=CePPCR_e_Req_No_Req}, provided-interface=VeSRMR_e_PPawl_Request
      VeSRMR_M_RegenBrkAxTorqCapFrnt: nonqueued-sender-com-spec{data-element=Value, init-value=0}, provided-interface=VeSRMR_M_RegenBrkAxTorqCapFrnt
      VeSRMR_M_RegenBrkAxTorqCapRear: nonqueued-sender-com-spec{data-element=Value, init-value=0}, provided-interface=VeSRMR_M_RegenBrkAxTorqCapRear
    require port SRMR_MedTEB_StartCheckpoint: client-com-spec=CheckpointReached, required-interface=WdgM_LocalSupervision
    require port SRMR_MedTEB_StopCheckpoint: client-com-spec=CheckpointReached, required-interface=WdgM_LocalSupervision
    behavior IB_SRMR: data-type-mapping=msADTtoIDTMapping, handle-termination-and-restart=NO-SUPPORT, included-data-type-set=data-type=TeSRMR_e_GRAR_Action
      timing event Event_MedTEB: start-on-event=SRMR_MedTEB, period=0.01
      init event Event_SRMR_ac_Init: start-on-event=SRMR_ac_Init
      init event Event_PwrOn: start-on-event=SRMR_PwrOn
      runnable SRMR_ac_Init
        data-send-points:
          9 x access:
            OUT_VeSRMR_e_MtrA_MdCmnd_Value: accessed-variable=VeSRMR_e_MtrA_MdCmnd.Value
            OUT_VeSRMR_e_MtrB_MdCmnd_Value: accessed-variable=VeSRMR_e_MtrB_MdCmnd.Value
            OUT_VeSRMR_e_VldtdTransShiftRngSt_Value: accessed-variable=VeSRMR_e_VldtdTransShiftRngSt.Value
            OUT_VeSRMR_e_GRAR_eAWD_TargetSts_Value: accessed-variable=VeSRMR_e_GRAR_eAWD_TargetSts.Value
            OUT_VeSRMR_e_GRAR_WED_TargetSts_Value: accessed-variable=VeSRMR_e_GRAR_WED_TargetSts.Value
            OUT_VeSRMR_e_GRAR_eLOCK_TargetSts_Value: accessed-variable=VeSRMR_e_GRAR_eLOCK_TargetSts.Value
            OUT_VeSRMR_e_GRAR_eLSD_TargetSts_Value: accessed-variable=VeSRMR_e_GRAR_eLSD_TargetSts.Value
            OUT_VeSRMR_e_LimitationMd_Value: accessed-variable=VeSRMR_e_LimitationMd.Value
            OUT_VeSRMR_e_PPawl_Request_Value: accessed-variable=VeSRMR_e_PPawl_Request.Value
      runnable SRMR_MedTEB
        data-receive-point-by-arguments:
          152 x access:
            IN_VeASMR_b_Lv2AutoStpFA_Value: accessed-variable=VeASMR_b_Lv2AutoStpFA.Value
            IN_VeASMR_b_Lv2AutoStrtFA_Value: accessed-variable=VeASMR_b_Lv2AutoStrtFA.Value
            IN_VeASMR_e_Lv2EngStrtStpMd_Value: accessed-variable=VeASMR_e_Lv2EngStrtStpMd.Value
            IN_VeASMR_n_Lv2EngSpd_Value: accessed-variable=VeASMR_n_Lv2EngSpd.Value
            IN_VeAXLR_M_ActualAxleTrq_Value: accessed-variable=VeAXLR_M_ActualAxleTrq.Value
            IN_VeAXLR_M_DrvrIntndedAxleTrq_Arb_Value: accessed-variable=VeAXLR_M_DrvrIntndedAxleTrq_Arb.Value
            IN_VeAXLR_M_FrntAxlTrqEst_Value: accessed-variable=VeAXLR_M_FrntAxlTrqEst.Value
            IN_VeAXLR_M_MaxAxleTrqCruise_Value: accessed-variable=VeAXLR_M_MaxAxleTrqCruise.Value
            IN_VeAXLR_M_MinAxleTrqCruise_Value: accessed-variable=VeAXLR_M_MinAxleTrqCruise.Value
            IN_VeAXLR_M_RrAxlTrqEst_Value: accessed-variable=VeAXLR_M_RrAxlTrqEst.Value
            IN_VeAXLR_b_ActualAxleTrqFA_Value: accessed-variable=VeAXLR_b_ActualAxleTrqFA.Value
            IN_VeCANR_e_CanLocEnblStatus_VeCANR_e_CanLocEnblStatus: accessed-variable=VeCANR_e_CanLocEnblStatus.VeCANR_e_CanLocEnblStatus
            IN_VeDTMR_b_DTRcmdFlt_Value: accessed-variable=VeDTMR_b_DTRcmdFlt.Value
            IN_VeDTMR_b_Lv2_OPD_ON_FA_Value: accessed-variable=VeDTMR_b_Lv2_OPD_ON_FA.Value
            IN_VeDTRR_b_DrvrIntndedAxleTrqRawFA_Value: accessed-variable=VeDTRR_b_DrvrIntndedAxleTrqRawFA.Value
            IN_VeDTRR_b_VehStndStillReq_OPD_Value: accessed-variable=VeDTRR_b_VehStndStillReq_OPD.Value
            IN_VeEMMR_b_Lv2APMStMode_FA_Value: accessed-variable=VeEMMR_b_Lv2APMStMode_FA.Value
            IN_VeESSR_e_EngStrtStpMd_Value: accessed-variable=VeESSR_e_EngStrtStpMd.Value
            IN_VeGENR_U_SetPVoltRq_Value: accessed-variable=VeGENR_U_SetPVoltRq.Value
            IN_VeGENR_b_SetPVoltRqFA_Value: accessed-variable=VeGENR_b_SetPVoltRqFA.Value
            IN_VeGENR_b_SrvcBattReChrgFlSts_Value: accessed-variable=VeGENR_b_SrvcBattReChrgFlSts.Value
            IN_VeGENR_e_stModeReq_Value: accessed-variable=VeGENR_e_stModeReq.Value
            IN_VeGRAR_b_Assign_RA_RIP_Ratio_Value: accessed-variable=VeGRAR_b_Assign_RA_RIP_Ratio.Value
            IN_VeGRAR_b_DisableECoast_Value: accessed-variable=VeGRAR_b_DisableECoast.Value
            IN_VeGRAR_b_DisableOPD_Value: accessed-variable=VeGRAR_b_DisableOPD.Value
            IN_VeGRAR_b_DisableRegenBrkTrq_Value: accessed-variable=VeGRAR_b_DisableRegenBrkTrq.Value
            IN_VeGRAR_b_EngageParkBrk_Value: accessed-variable=VeGRAR_b_EngageParkBrk.Value
            IN_VeGRAR_b_TotMtrTrqIncRampEnbl_Value: accessed-variable=VeGRAR_b_TotMtrTrqIncRampEnbl.Value
            IN_VeGRAR_e_MSSBEV_Action_Value: accessed-variable=VeGRAR_e_MSSBEV_Action.Value
            IN_VeGRAR_e_PRND_Req_Value: accessed-variable=VeGRAR_e_PRND_Req.Value
            IN_VeGRAR_e_ParkPawlReq_Value: accessed-variable=VeGRAR_e_ParkPawlReq.Value
            IN_VeGRAR_e_TotMtrTrqRmdlActn_Value: accessed-variable=VeGRAR_e_TotMtrTrqRmdlActn.Value
            IN_VeGRAR_r_RA_RIP_Ratio_Value: accessed-variable=VeGRAR_r_RA_RIP_Ratio.Value
            IN_VeGSMR_b_ApplyEPB_Value: accessed-variable=VeGSMR_b_ApplyEPB.Value
            IN_VeGSMR_b_MissedNeutralReqFlt_Value: accessed-variable=VeGSMR_b_MissedNeutralReqFlt.Value
            IN_VeGSMR_b_MissedParkReqFlt_Value: accessed-variable=VeGSMR_b_MissedParkReqFlt.Value
            IN_VeGSMR_b_PpawlInsrtFailed_Value: accessed-variable=VeGSMR_b_PpawlInsrtFailed.Value
            IN_VeGSMR_b_PpawlInsrtMntrFailed_Value: accessed-variable=VeGSMR_b_PpawlInsrtMntrFailed.Value
            IN_VeGSMR_b_SecureVehicle_Value: accessed-variable=VeGSMR_b_SecureVehicle.Value
            IN_VeGSMR_e_DrvrPRNDRq_Value: accessed-variable=VeGSMR_e_DrvrPRNDRq.Value
            IN_VeHMIR_e_ShifterPOS_Value: accessed-variable=VeHMIR_e_ShifterPOS.Value
            IN_VeHMIR_e_TransWarn2_Value: accessed-variable=VeHMIR_e_TransWarn2.Value
            IN_VeHPMR_b_MtrSystemActive_Value: accessed-variable=VeHPMR_b_MtrSystemActive.Value
            IN_VeHPMR_e_HighVltCntctrCntrl_Value: accessed-variable=VeHPMR_e_HighVltCntctrCntrl.Value
            IN_VeHTDR_M_MtrB_TorqCmnd_Value: accessed-variable=VeHTDR_M_MtrB_TorqCmnd.Value
            IN_VeHTDR_b_AHH_ModifyAccel_Req_Value: accessed-variable=VeHTDR_b_AHH_ModifyAccel_Req.Value
            IN_VeHTDR_e_AHH_ApplyRelease_Req_Value: accessed-variable=VeHTDR_e_AHH_ApplyRelease_Req.Value
            IN_VeHTDR_e_MtrB_MdCmnd_Value: accessed-variable=VeHTDR_e_MtrB_MdCmnd.Value
            IN_VeICSR_M_EngCLITerm_Value: accessed-variable=VeICSR_M_EngCLITerm.Value
            IN_VeLTIR_M_Lv2BrkTrq_Value: accessed-variable=VeLTIR_M_Lv2BrkTrq.Value
            IN_VeLTIR_M_Lv2MtrA_TrqCmnd_Value: accessed-variable=VeLTIR_M_Lv2MtrA_TrqCmnd.Value
            IN_VeLTIR_b_Lv2APM_HVBatVlt_FA_Value: accessed-variable=VeLTIR_b_Lv2APM_HVBatVlt_FA.Value
            IN_VeLTIR_b_Lv2BrkPdlStatFlt_Value: accessed-variable=VeLTIR_b_Lv2BrkPdlStatFlt.Value
            IN_VeLTIR_b_Lv2BrkTrqFlt_Value: accessed-variable=VeLTIR_b_Lv2BrkTrqFlt.Value
            IN_VeLTIR_b_Lv2HV_BatCntctrStat_FA_Value: accessed-variable=VeLTIR_b_Lv2HV_BatCntctrStat_FA.Value
            IN_VeLTIR_b_Lv2HV_BatModTempMax_FA_Value: accessed-variable=VeLTIR_b_Lv2HV_BatModTempMax_FA.Value
            IN_VeLTIR_b_Lv2HV_BatSOC_FA_Value: accessed-variable=VeLTIR_b_Lv2HV_BatSOC_FA.Value
            IN_VeLTIR_b_Lv2KeySts_FA_Value: accessed-variable=VeLTIR_b_Lv2KeySts_FA.Value
            IN_VeLTIR_b_Lv2MtrA_MaxTrq_FA_Value: accessed-variable=VeLTIR_b_Lv2MtrA_MaxTrq_FA.Value
            IN_VeLTIR_b_Lv2MtrA_MinTrq_FA_Value: accessed-variable=VeLTIR_b_Lv2MtrA_MinTrq_FA.Value
            IN_VeLTIR_b_Lv2MtrA_TrqAchieved_FA_Value: accessed-variable=VeLTIR_b_Lv2MtrA_TrqAchieved_FA.Value
            IN_VeLTIR_b_Lv2MtrB_MaxTrq_FA_Value: accessed-variable=VeLTIR_b_Lv2MtrB_MaxTrq_FA.Value
            IN_VeLTIR_b_Lv2MtrB_MinTrq_FA_Value: accessed-variable=VeLTIR_b_Lv2MtrB_MinTrq_FA.Value
            IN_VeLTIR_e_Lv2BrkPdlStat_Value: accessed-variable=VeLTIR_e_Lv2BrkPdlStat.Value
            IN_VeLTIR_e_Lv2KeySts_Value: accessed-variable=VeLTIR_e_Lv2KeySts.Value
            IN_VeLTIR_e_Lv2MtrA_MdCmnd_Value: accessed-variable=VeLTIR_e_Lv2MtrA_MdCmnd.Value
            IN_VeMMMR_b_Lv2MtrMd_DBC_Fault_Value: accessed-variable=VeMMMR_b_Lv2MtrMd_DBC_Fault.Value
            IN_VeMTIR_M_MtrA_TorqAchieved_Value: accessed-variable=VeMTIR_M_MtrA_TorqAchieved.Value
            IN_VeMTIR_b_MtrA_TorqAchievedFA_Value: accessed-variable=VeMTIR_b_MtrA_TorqAchievedFA.Value
            IN_VeOHSR_n_IdleSpeed_Target_Value: accessed-variable=VeOHSR_n_IdleSpeed_Target.Value
            IN_VePPCR_e_PPawl_HW_Request_Value: accessed-variable=VePPCR_e_PPawl_HW_Request.Value
            IN_VePSMR_Pct_Lv2AccelPdlPos_Value: accessed-variable=VePSMR_Pct_Lv2AccelPdlPos.Value
            IN_VePSMR_b_Lv2AccelPdlPosFlt_Value: accessed-variable=VePSMR_b_Lv2AccelPdlPosFlt.Value
            IN_VePSMR_e_Lv2PVSMode_Value: accessed-variable=VePSMR_e_Lv2PVSMode.Value
            IN_VeRGNR_M_AeCoastTorqDiff_Value: accessed-variable=VeRGNR_M_AeCoastTorqDiff.Value
            IN_VeRGNR_M_EstRegenBrkAxTorq_Value: accessed-variable=VeRGNR_M_EstRegenBrkAxTorq.Value
            IN_VeRGNR_M_RegenBrkOutTorqCap_CAN_Value: accessed-variable=VeRGNR_M_RegenBrkOutTorqCap_CAN.Value
            IN_VeRGNR_M_RegenBrkOutTorqCap_Frnt_Value: accessed-variable=VeRGNR_M_RegenBrkOutTorqCap_Frnt.Value
            IN_VeRGNR_M_RegenBrkOutTorqCap_Rear_Value: accessed-variable=VeRGNR_M_RegenBrkOutTorqCap_Rear.Value
            IN_VeRGNR_b_AeCoastTorqDiffActv_Value: accessed-variable=VeRGNR_b_AeCoastTorqDiffActv.Value
            IN_VeRGNR_b_EstRegenBrkAxTorqFA_Value: accessed-variable=VeRGNR_b_EstRegenBrkAxTorqFA.Value
            IN_VeRGNR_b_RegenBrkAxTorqCapFA_Value: accessed-variable=VeRGNR_b_RegenBrkAxTorqCapFA.Value
            IN_VeSABR_b_SL2outBEV_VDAB_WED_SafActive_Value: accessed-variable=VeSABR_b_SL2outBEV_VDAB_WED_SafActive.Value
            IN_VeSABR_b_SL2outBEV_VDAB_eAWD_SafActive_Value: accessed-variable=VeSABR_b_SL2outBEV_VDAB_eAWD_SafActive.Value
            IN_VeSABR_b_SL2outBEV_VDAB_eLOCK_SafActive_Value: accessed-variable=VeSABR_b_SL2outBEV_VDAB_eLOCK_SafActive.Value
            IN_VeSABR_b_SL2outBEV_VDAB_eLSD_SafActive_Value: accessed-variable=VeSABR_b_SL2outBEV_VDAB_eLSD_SafActive.Value
            IN_VeSCMR_M_Lv2MtrA_MaxTrq_Value: accessed-variable=VeSCMR_M_Lv2MtrA_MaxTrq.Value
            IN_VeSCMR_M_Lv2MtrA_MinTrq_Value: accessed-variable=VeSCMR_M_Lv2MtrA_MinTrq.Value
            IN_VeSCMR_M_Lv2MtrA_TrqAchieved_Value: accessed-variable=VeSCMR_M_Lv2MtrA_TrqAchieved.Value
            IN_VeSCMR_M_Lv2MtrB_MaxTrq_Value: accessed-variable=VeSCMR_M_Lv2MtrB_MaxTrq.Value
            IN_VeSCMR_M_Lv2MtrB_MinTrq_Value: accessed-variable=VeSCMR_M_Lv2MtrB_MinTrq.Value
            IN_VeSCMR_Pct_Lv2HV_BatSOC_Value: accessed-variable=VeSCMR_Pct_Lv2HV_BatSOC.Value
            IN_VeSCMR_T_Lv2HV_BatModTempMax_Value: accessed-variable=VeSCMR_T_Lv2HV_BatModTempMax.Value
            IN_VeSCMR_U_BPCM_HVBatVlt_Value: accessed-variable=VeSCMR_U_BPCM_HVBatVlt.Value
            IN_VeSCMR_U_HVBusVolt_Value: accessed-variable=VeSCMR_U_HVBusVolt.Value
            IN_VeSCMR_U_InvrtrA_HVBatVlt_Value: accessed-variable=VeSCMR_U_InvrtrA_HVBatVlt.Value
            IN_VeSCMR_U_Lv2APM_HVBatVlt_Value: accessed-variable=VeSCMR_U_Lv2APM_HVBatVlt.Value
            IN_VeSCMR_U_Lv2EVRDesVSetP_Value: accessed-variable=VeSCMR_U_Lv2EVRDesVSetP.Value
            IN_VeSCMR_b_ASC_Req_Value: accessed-variable=VeSCMR_b_ASC_Req.Value
            IN_VeSCMR_b_BPCM_HVBatVltFA_Value: accessed-variable=VeSCMR_b_BPCM_HVBatVltFA.Value
            IN_VeSCMR_b_Lv2EVRDesVSetP_FA_Value: accessed-variable=VeSCMR_b_Lv2EVRDesVSetP_FA.Value
            IN_VeSCMR_b_Lv2HV_BatCntctrOpn_Value: accessed-variable=VeSCMR_b_Lv2HV_BatCntctrOpn.Value
            IN_VeSCMR_b_Lv2HV_BatCntctrReq_Value: accessed-variable=VeSCMR_b_Lv2HV_BatCntctrReq.Value
            IN_VeSCMR_b_Lv2MtrAFlt_HV_CntctrOpnRq_Value: accessed-variable=VeSCMR_b_Lv2MtrAFlt_HV_CntctrOpnRq.Value
            IN_VeSCMR_b_Lv2MtrBFlt_HV_CntctrOpnRq_Value: accessed-variable=VeSCMR_b_Lv2MtrBFlt_HV_CntctrOpnRq.Value
            IN_VeSCMR_b_Lv2MtrCFlt_HV_CntctrOpnRq_Value: accessed-variable=VeSCMR_b_Lv2MtrCFlt_HV_CntctrOpnRq.Value
            IN_VeSCMR_b_MSSBEV_Vbatt_mV_UV_Value: accessed-variable=VeSCMR_b_MSSBEV_Vbatt_mV_UV.Value
            IN_VeSCMR_b_SharedMemFlt_Value: accessed-variable=VeSCMR_b_SharedMemFlt.Value
            IN_VeSCMR_e_Lv2APM_FailureReason_Value: accessed-variable=VeSCMR_e_Lv2APM_FailureReason.Value
            IN_VeSCMR_e_Lv2APM_FailureType_Value: accessed-variable=VeSCMR_e_Lv2APM_FailureType.Value
            IN_VeSCMR_e_Lv2ESS_EngStateEE_Value: accessed-variable=VeSCMR_e_Lv2ESS_EngStateEE.Value
            IN_VeSCMR_e_Lv2HV_BatCntctrStat_Value: accessed-variable=VeSCMR_e_Lv2HV_BatCntctrStat.Value
            IN_VeSCMR_e_Lv2MtrA_InvrtrSts_Value: accessed-variable=VeSCMR_e_Lv2MtrA_InvrtrSts.Value
            IN_VeSCMR_e_MSSBEV_Action_Value: accessed-variable=VeSCMR_e_MSSBEV_Action.Value
            IN_VeSCMR_e_MSSBEV_HVEM_TargetSts_Value: accessed-variable=VeSCMR_e_MSSBEV_HVEM_TargetSts.Value
            IN_VeSRAR_b_HybFeedback_ECM_Value: accessed-variable=VeSRAR_b_HybFeedback_ECM.Value
            IN_VeSRAR_b_Popup_Msg15_Value: accessed-variable=VeSRAR_b_Popup_Msg15.Value
            IN_VeSRAR_b_Popup_Msg9_Value: accessed-variable=VeSRAR_b_Popup_Msg9.Value
            IN_VeSRAR_e_EPB_Hold_Req_Value: accessed-variable=VeSRAR_e_EPB_Hold_Req.Value
            IN_VeSRAR_n_HCPMaxEngRPM_Value: accessed-variable=VeSRAR_n_HCPMaxEngRPM.Value
            IN_VeSSMR_b_VehSpdFA_Value: accessed-variable=VeSSMR_b_VehSpdFA.Value
            IN_VeSSMR_b_VehSpdRatFailed_Value: accessed-variable=VeSSMR_b_VehSpdRatFailed.Value
            IN_VeSSMR_n_MtrBSpd_Value: accessed-variable=VeSSMR_n_MtrBSpd.Value
            IN_VeSSMR_v_VehSpd_Value: accessed-variable=VeSSMR_v_VehSpd.Value
            IN_VeSTMR_b_Allow_OpenBattCntctr_Value: accessed-variable=VeSTMR_b_Allow_OpenBattCntctr.Value
            IN_VeSTMR_b_DrvrIntndedAxleTrqFA_Value: accessed-variable=VeSTMR_b_DrvrIntndedAxleTrqFA.Value
            IN_VeSTMR_b_EngTorqCmndMntrFlt_Value: accessed-variable=VeSTMR_b_EngTorqCmndMntrFlt.Value
            IN_VeSTMR_b_FrntAxlTrqEstFA_Value: accessed-variable=VeSTMR_b_FrntAxlTrqEstFA.Value
            IN_VeSTMR_b_FrontAxleTrqEstMntrFlt_Value: accessed-variable=VeSTMR_b_FrontAxleTrqEstMntrFlt.Value
            IN_VeSTMR_b_Lv2BattWeldFA_Value: accessed-variable=VeSTMR_b_Lv2BattWeldFA.Value
            IN_VeSTMR_b_OutTrq_MaxLimFail_Value: accessed-variable=VeSTMR_b_OutTrq_MaxLimFail.Value
            IN_VeSTMR_b_OutTrq_MinLimFail_Value: accessed-variable=VeSTMR_b_OutTrq_MinLimFail.Value
            IN_VeSTMR_b_P1fEstMntrFlt_Value: accessed-variable=VeSTMR_b_P1fEstMntrFlt.Value
            IN_VeSTMR_b_P1fNotGeneratorMode_Value: accessed-variable=VeSTMR_b_P1fNotGeneratorMode.Value
            IN_VeSTMR_b_P4TrqMntrFlt_Value: accessed-variable=VeSTMR_b_P4TrqMntrFlt.Value
            IN_VeSTMR_b_RgnEstMntrFlt_Value: accessed-variable=VeSTMR_b_RgnEstMntrFlt.Value
            IN_VeSTMR_b_RrAxlTrqEstFA_Value: accessed-variable=VeSTMR_b_RrAxlTrqEstFA.Value
            IN_VeSTMR_b_TransOutTrqCmdFlt_Value: accessed-variable=VeSTMR_b_TransOutTrqCmdFlt.Value
            IN_VeSTMR_b_TrqSplit_OS_US_Value: accessed-variable=VeSTMR_b_TrqSplit_OS_US.Value
            IN_VeSTMR_b_UnIntendedVehMovInNeutral_Value: accessed-variable=VeSTMR_b_UnIntendedVehMovInNeutral.Value
            IN_VeTITR_M_SnsdEng_Flt_Value: accessed-variable=VeTITR_M_SnsdEng_Flt.Value
            IN_VeTITR_b_SnsdTi_notVld_Value: accessed-variable=VeTITR_b_SnsdTi_notVld.Value
            IN_VeTRAR_M_EngTorqCmndImmed_Value: accessed-variable=VeTRAR_M_EngTorqCmndImmed.Value
            IN_VeTRAR_M_HybCmndEngTorqPrdtd_Value: accessed-variable=VeTRAR_M_HybCmndEngTorqPrdtd.Value
            IN_VeTRAR_b_EngDFCOReq_Value: accessed-variable=VeTRAR_b_EngDFCOReq.Value
            IN_VeTRAR_e_EngCntrlMode_Value: accessed-variable=VeTRAR_e_EngCntrlMode.Value
            IN_VeTRAR_e_HybCmndEngTorqRespTyp_Value: accessed-variable=VeTRAR_e_HybCmndEngTorqRespTyp.Value
            IN_VeTRGR_b_GatedParkSw_Value: accessed-variable=VeTRGR_b_GatedParkSw.Value
            IN_VeTRGR_e_CurrentGear_Value: accessed-variable=VeTRGR_e_CurrentGear.Value
            IN_VeTRGR_e_PRNDLReq_Value: accessed-variable=VeTRGR_e_PRNDLReq.Value
            IN_VeTRGR_e_TargetGear_Value: accessed-variable=VeTRGR_e_TargetGear.Value
            IN_VeTRGR_e_VldtdTransShiftRngSt_Value: accessed-variable=VeTRGR_e_VldtdTransShiftRngSt.Value
        data-send-points:
          67 x access:
            OUT_VeSRMR_b_Lv2AccelPdlPosFlt_Value: accessed-variable=VeSRMR_b_Lv2AccelPdlPosFlt.Value
            OUT_VeSRMR_Pct_Lv2AccelPdlPos_Value: accessed-variable=VeSRMR_Pct_Lv2AccelPdlPos.Value
            OUT_VeSRMR_M_MaxAxleTrqCruise_Value: accessed-variable=VeSRMR_M_MaxAxleTrqCruise.Value
            OUT_VeSRMR_M_MinAxleTrqCruise_Value: accessed-variable=VeSRMR_M_MinAxleTrqCruise.Value
            OUT_VeSRMR_M_ActualAxleTrq_Value: accessed-variable=VeSRMR_M_ActualAxleTrq.Value
            OUT_VeSRMR_e_EngCntrlMode_Value: accessed-variable=VeSRMR_e_EngCntrlMode.Value
            OUT_VeSRMR_M_EngTrqCmndImmed_Value: accessed-variable=VeSRMR_M_EngTrqCmndImmed.Value
            OUT_VeSRMR_M_EngTrqCmndPrdtd_Value: accessed-variable=VeSRMR_M_EngTrqCmndPrdtd.Value
            OUT_VeSRMR_e_HybCmndEngTorqRespTyp_Value: accessed-variable=VeSRMR_e_HybCmndEngTorqRespTyp.Value
            OUT_VeSRMR_b_EngDFCOReq_Value: accessed-variable=VeSRMR_b_EngDFCOReq.Value
            OUT_VeSRMR_b_SnsdTi_notVld_Value: accessed-variable=VeSRMR_b_SnsdTi_notVld.Value
            OUT_VeSRMR_b_HybFeedback_ECM_Value: accessed-variable=VeSRMR_b_HybFeedback_ECM.Value
            OUT_VeSRMR_M_EngCLITerm_Value: accessed-variable=VeSRMR_M_EngCLITerm.Value
            OUT_VeSRMR_M_EstRegenBrkAxTorq_Value: accessed-variable=VeSRMR_M_EstRegenBrkAxTorq.Value
            OUT_VeSRMR_M_RegenBrkAxTorqCap_Value: accessed-variable=VeSRMR_M_RegenBrkAxTorqCap.Value
            OUT_VeSRMR_e_MtrA_MdCmnd_Value: accessed-variable=VeSRMR_e_MtrA_MdCmnd.Value
            OUT_VeSRMR_M_MtrA_TorqCmnd_Value: accessed-variable=VeSRMR_M_MtrA_TorqCmnd.Value
            OUT_VeSRMR_M_MtrB_TorqCmnd_Value: accessed-variable=VeSRMR_M_MtrB_TorqCmnd.Value
            OUT_VeSRMR_e_MtrB_MdCmnd_Value: accessed-variable=VeSRMR_e_MtrB_MdCmnd.Value
            OUT_VeSRMR_M_SnsdEng_Flt_Value: accessed-variable=VeSRMR_M_SnsdEng_Flt.Value
            OUT_VeSRMR_e_CurrentGear_Value: accessed-variable=VeSRMR_e_CurrentGear.Value
            OUT_VeSRMR_e_TargetGear_Value: accessed-variable=VeSRMR_e_TargetGear.Value
            OUT_VeSRMR_e_EPB_Hold_Req_Value: accessed-variable=VeSRMR_e_EPB_Hold_Req.Value
            OUT_VeSRMR_e_PRNDLReq_Value: accessed-variable=VeSRMR_e_PRNDLReq.Value
            OUT_VeSRMR_e_ShifterPOS_Value: accessed-variable=VeSRMR_e_ShifterPOS.Value
            OUT_VeSRMR_e_VldtdTransShiftRngSt_Value: accessed-variable=VeSRMR_e_VldtdTransShiftRngSt.Value
            OUT_VeSRMR_b_GatedParkSw_Value: accessed-variable=VeSRMR_b_GatedParkSw.Value
            OUT_VeSRMR_b_EstRegenBrkAxTorqFA_Value: accessed-variable=VeSRMR_b_EstRegenBrkAxTorqFA.Value
            OUT_VeSRMR_b_RegenBrkAxTorqCapFA_Value: accessed-variable=VeSRMR_b_RegenBrkAxTorqCapFA.Value
            OUT_VeSRMR_e_TransWarn2_Value: accessed-variable=VeSRMR_e_TransWarn2.Value
            OUT_VeSRMR_e_AHH_ApplyRelease_Req_Value: accessed-variable=VeSRMR_e_AHH_ApplyRelease_Req.Value
            OUT_VeSRMR_b_AHH_ModifyAccel_Req_Value: accessed-variable=VeSRMR_b_AHH_ModifyAccel_Req.Value
            OUT_VeSRMR_e_HEV_ESS_Mode_Value: accessed-variable=VeSRMR_e_HEV_ESS_Mode.Value
            OUT_VeSRMR_M_BSGActualTorque_Value: accessed-variable=VeSRMR_M_BSGActualTorque.Value
            OUT_VeSRMR_b_BSGActualTorqueFA_Value: accessed-variable=VeSRMR_b_BSGActualTorqueFA.Value
            OUT_VeSRMR_n_BSGChrgIdleSpeedTarget_Value: accessed-variable=VeSRMR_n_BSGChrgIdleSpeedTarget.Value
            OUT_VeSRMR_n_HCPMaxEngRPM_Value: accessed-variable=VeSRMR_n_HCPMaxEngRPM.Value
            OUT_VeSRMR_e_APM_OperModeEnable_Value: accessed-variable=VeSRMR_e_APM_OperModeEnable.Value
            OUT_VeSRMR_U_APM_VdcLvSetP_Value: accessed-variable=VeSRMR_U_APM_VdcLvSetP.Value
            OUT_VeSRMR_b_APM_VdcLvSetP_FA_Value: accessed-variable=VeSRMR_b_APM_VdcLvSetP_FA.Value
            OUT_VeSRMR_b_BSGChrgIdleSpeedTargetFA_Value: accessed-variable=VeSRMR_b_BSGChrgIdleSpeedTargetFA.Value
            OUT_VeSRMR_b_HCPMaxEngRPMFA_Value: accessed-variable=VeSRMR_b_HCPMaxEngRPMFA.Value
            OUT_VeSRMR_M_SplitFrntTrqReq_Value: accessed-variable=VeSRMR_M_SplitFrntTrqReq.Value
            OUT_VeSRMR_M_SplitRearTrqReq_Value: accessed-variable=VeSRMR_M_SplitRearTrqReq.Value
            OUT_VeSRMR_e_MainHighVltCntctrCmd_Value: accessed-variable=VeSRMR_e_MainHighVltCntctrCmd.Value
            OUT_VeSRMR_b_Popup_Msg15_Value: accessed-variable=VeSRMR_b_Popup_Msg15.Value
            OUT_VeSRMR_b_Popup_Msg9_Value: accessed-variable=VeSRMR_b_Popup_Msg9.Value
            OUT_VeSRMR_b_AeCoastTorqDiffActv_Value: accessed-variable=VeSRMR_b_AeCoastTorqDiffActv.Value
            OUT_VeSRMR_M_AeCoastTorqDiff_Value: accessed-variable=VeSRMR_M_AeCoastTorqDiff.Value
            OUT_VeSRMR_b_VehStndStillReq_OPD_Value: accessed-variable=VeSRMR_b_VehStndStillReq_OPD.Value
            OUT_VeSRMR_b_ActualAxleTrqFA_Value: accessed-variable=VeSRMR_b_ActualAxleTrqFA.Value
            OUT_VeSRMR_M_DrvrIntndedAxleTrq_Value: accessed-variable=VeSRMR_M_DrvrIntndedAxleTrq.Value
            OUT_VeSRMR_b_DrvrIntndedAxleTrqFA_Value: accessed-variable=VeSRMR_b_DrvrIntndedAxleTrqFA.Value
            OUT_VeSRMR_e_stModeReq_Value: accessed-variable=VeSRMR_e_stModeReq.Value
            OUT_VeSRMR_b_CrashDischarge_Value: accessed-variable=VeSRMR_b_CrashDischarge.Value
            OUT_VeSRMR_b_SrvcBattReChrgFlSts_Value: accessed-variable=VeSRMR_b_SrvcBattReChrgFlSts.Value
            OUT_VeSRMR_e_GRAR_eAWD_TargetSts_Value: accessed-variable=VeSRMR_e_GRAR_eAWD_TargetSts.Value
            OUT_VeSRMR_e_GRAR_WED_TargetSts_Value: accessed-variable=VeSRMR_e_GRAR_WED_TargetSts.Value
            OUT_VeSRMR_e_GRAR_eLOCK_TargetSts_Value: accessed-variable=VeSRMR_e_GRAR_eLOCK_TargetSts.Value
            OUT_VeSRMR_e_GRAR_eLSD_TargetSts_Value: accessed-variable=VeSRMR_e_GRAR_eLSD_TargetSts.Value
            OUT_VeSRMR_e_LimitationMd_Value: accessed-variable=VeSRMR_e_LimitationMd.Value
            OUT_VeSRMR_b_MtrMdVldtnFltErr_Value: accessed-variable=VeSRMR_b_MtrMdVldtnFltErr.Value
            OUT_VeSRMR_v_VehSpd_Value: accessed-variable=VeSRMR_v_VehSpd.Value
            OUT_VeSRMR_b_VehSpdFA_Value: accessed-variable=VeSRMR_b_VehSpdFA.Value
            OUT_VeSRMR_e_PPawl_Request_Value: accessed-variable=VeSRMR_e_PPawl_Request.Value
            OUT_VeSRMR_M_RegenBrkAxTorqCapFrnt_Value: accessed-variable=VeSRMR_M_RegenBrkAxTorqCapFrnt.Value
            OUT_VeSRMR_M_RegenBrkAxTorqCapRear_Value: accessed-variable=VeSRMR_M_RegenBrkAxTorqCapRear.Value
        sync call SC_SRMR_MedTEB_StartCheckpoint_CheckpointReached: operation=SRMR_MedTEB_StartCheckpoint.CheckpointReached, timeout=1E-06
        sync call SC_SRMR_MedTEB_StopCheckpoint_CheckpointReached: operation=SRMR_MedTEB_StopCheckpoint.CheckpointReached, timeout=1E-06
      runnable SRMR_PwrOn
        data-send-points:
          67 x access:
            OUT_VeSRMR_M_MaxAxleTrqCruise_Value: accessed-variable=VeSRMR_M_MaxAxleTrqCruise.Value
            OUT_VeSRMR_M_MinAxleTrqCruise_Value: accessed-variable=VeSRMR_M_MinAxleTrqCruise.Value
            OUT_VeSRMR_M_ActualAxleTrq_Value: accessed-variable=VeSRMR_M_ActualAxleTrq.Value
            OUT_VeSRMR_e_EngCntrlMode_Value: accessed-variable=VeSRMR_e_EngCntrlMode.Value
            OUT_VeSRMR_M_EngTrqCmndImmed_Value: accessed-variable=VeSRMR_M_EngTrqCmndImmed.Value
            OUT_VeSRMR_M_EngTrqCmndPrdtd_Value: accessed-variable=VeSRMR_M_EngTrqCmndPrdtd.Value
            OUT_VeSRMR_e_HybCmndEngTorqRespTyp_Value: accessed-variable=VeSRMR_e_HybCmndEngTorqRespTyp.Value
            OUT_VeSRMR_b_EngDFCOReq_Value: accessed-variable=VeSRMR_b_EngDFCOReq.Value
            OUT_VeSRMR_b_SnsdTi_notVld_Value: accessed-variable=VeSRMR_b_SnsdTi_notVld.Value
            OUT_VeSRMR_b_HybFeedback_ECM_Value: accessed-variable=VeSRMR_b_HybFeedback_ECM.Value
            OUT_VeSRMR_M_EngCLITerm_Value: accessed-variable=VeSRMR_M_EngCLITerm.Value
            OUT_VeSRMR_M_EstRegenBrkAxTorq_Value: accessed-variable=VeSRMR_M_EstRegenBrkAxTorq.Value
            OUT_VeSRMR_M_RegenBrkAxTorqCap_Value: accessed-variable=VeSRMR_M_RegenBrkAxTorqCap.Value
            OUT_VeSRMR_e_MtrA_MdCmnd_Value: accessed-variable=VeSRMR_e_MtrA_MdCmnd.Value
            OUT_VeSRMR_M_MtrA_TorqCmnd_Value: accessed-variable=VeSRMR_M_MtrA_TorqCmnd.Value
            OUT_VeSRMR_M_MtrB_TorqCmnd_Value: accessed-variable=VeSRMR_M_MtrB_TorqCmnd.Value
            OUT_VeSRMR_e_MtrB_MdCmnd_Value: accessed-variable=VeSRMR_e_MtrB_MdCmnd.Value
            OUT_VeSRMR_M_SnsdEng_Flt_Value: accessed-variable=VeSRMR_M_SnsdEng_Flt.Value
            OUT_VeSRMR_e_CurrentGear_Value: accessed-variable=VeSRMR_e_CurrentGear.Value
            OUT_VeSRMR_e_TargetGear_Value: accessed-variable=VeSRMR_e_TargetGear.Value
            OUT_VeSRMR_e_EPB_Hold_Req_Value: accessed-variable=VeSRMR_e_EPB_Hold_Req.Value
            OUT_VeSRMR_e_PRNDLReq_Value: accessed-variable=VeSRMR_e_PRNDLReq.Value
            OUT_VeSRMR_e_ShifterPOS_Value: accessed-variable=VeSRMR_e_ShifterPOS.Value
            OUT_VeSRMR_e_VldtdTransShiftRngSt_Value: accessed-variable=VeSRMR_e_VldtdTransShiftRngSt.Value
            OUT_VeSRMR_b_GatedParkSw_Value: accessed-variable=VeSRMR_b_GatedParkSw.Value
            OUT_VeSRMR_b_EstRegenBrkAxTorqFA_Value: accessed-variable=VeSRMR_b_EstRegenBrkAxTorqFA.Value
            OUT_VeSRMR_b_RegenBrkAxTorqCapFA_Value: accessed-variable=VeSRMR_b_RegenBrkAxTorqCapFA.Value
            OUT_VeSRMR_e_TransWarn2_Value: accessed-variable=VeSRMR_e_TransWarn2.Value
            OUT_VeSRMR_e_AHH_ApplyRelease_Req_Value: accessed-variable=VeSRMR_e_AHH_ApplyRelease_Req.Value
            OUT_VeSRMR_b_AHH_ModifyAccel_Req_Value: accessed-variable=VeSRMR_b_AHH_ModifyAccel_Req.Value
            OUT_VeSRMR_e_HEV_ESS_Mode_Value: accessed-variable=VeSRMR_e_HEV_ESS_Mode.Value
            OUT_VeSRMR_M_BSGActualTorque_Value: accessed-variable=VeSRMR_M_BSGActualTorque.Value
            OUT_VeSRMR_b_BSGActualTorqueFA_Value: accessed-variable=VeSRMR_b_BSGActualTorqueFA.Value
            OUT_VeSRMR_n_BSGChrgIdleSpeedTarget_Value: accessed-variable=VeSRMR_n_BSGChrgIdleSpeedTarget.Value
            OUT_VeSRMR_n_HCPMaxEngRPM_Value: accessed-variable=VeSRMR_n_HCPMaxEngRPM.Value
            OUT_VeSRMR_e_APM_OperModeEnable_Value: accessed-variable=VeSRMR_e_APM_OperModeEnable.Value
            OUT_VeSRMR_U_APM_VdcLvSetP_Value: accessed-variable=VeSRMR_U_APM_VdcLvSetP.Value
            OUT_VeSRMR_b_APM_VdcLvSetP_FA_Value: accessed-variable=VeSRMR_b_APM_VdcLvSetP_FA.Value
            OUT_VeSRMR_b_BSGChrgIdleSpeedTargetFA_Value: accessed-variable=VeSRMR_b_BSGChrgIdleSpeedTargetFA.Value
            OUT_VeSRMR_b_HCPMaxEngRPMFA_Value: accessed-variable=VeSRMR_b_HCPMaxEngRPMFA.Value
            OUT_VeSRMR_M_SplitFrntTrqReq_Value: accessed-variable=VeSRMR_M_SplitFrntTrqReq.Value
            OUT_VeSRMR_M_SplitRearTrqReq_Value: accessed-variable=VeSRMR_M_SplitRearTrqReq.Value
            OUT_VeSRMR_e_MainHighVltCntctrCmd_Value: accessed-variable=VeSRMR_e_MainHighVltCntctrCmd.Value
            OUT_VeSRMR_b_Lv2AccelPdlPosFlt_Value: accessed-variable=VeSRMR_b_Lv2AccelPdlPosFlt.Value
            OUT_VeSRMR_Pct_Lv2AccelPdlPos_Value: accessed-variable=VeSRMR_Pct_Lv2AccelPdlPos.Value
            OUT_VeSRMR_b_Popup_Msg15_Value: accessed-variable=VeSRMR_b_Popup_Msg15.Value
            OUT_VeSRMR_b_Popup_Msg9_Value: accessed-variable=VeSRMR_b_Popup_Msg9.Value
            OUT_VeSRMR_b_AeCoastTorqDiffActv_Value: accessed-variable=VeSRMR_b_AeCoastTorqDiffActv.Value
            OUT_VeSRMR_M_AeCoastTorqDiff_Value: accessed-variable=VeSRMR_M_AeCoastTorqDiff.Value
            OUT_VeSRMR_b_VehStndStillReq_OPD_Value: accessed-variable=VeSRMR_b_VehStndStillReq_OPD.Value
            OUT_VeSRMR_b_ActualAxleTrqFA_Value: accessed-variable=VeSRMR_b_ActualAxleTrqFA.Value
            OUT_VeSRMR_M_DrvrIntndedAxleTrq_Value: accessed-variable=VeSRMR_M_DrvrIntndedAxleTrq.Value
            OUT_VeSRMR_b_DrvrIntndedAxleTrqFA_Value: accessed-variable=VeSRMR_b_DrvrIntndedAxleTrqFA.Value
            OUT_VeSRMR_e_stModeReq_Value: accessed-variable=VeSRMR_e_stModeReq.Value
            OUT_VeSRMR_b_CrashDischarge_Value: accessed-variable=VeSRMR_b_CrashDischarge.Value
            OUT_VeSRMR_b_SrvcBattReChrgFlSts_Value: accessed-variable=VeSRMR_b_SrvcBattReChrgFlSts.Value
            OUT_VeSRMR_e_GRAR_eAWD_TargetSts_Value: accessed-variable=VeSRMR_e_GRAR_eAWD_TargetSts.Value
            OUT_VeSRMR_e_GRAR_WED_TargetSts_Value: accessed-variable=VeSRMR_e_GRAR_WED_TargetSts.Value
            OUT_VeSRMR_e_GRAR_eLOCK_TargetSts_Value: accessed-variable=VeSRMR_e_GRAR_eLOCK_TargetSts.Value
            OUT_VeSRMR_e_GRAR_eLSD_TargetSts_Value: accessed-variable=VeSRMR_e_GRAR_eLSD_TargetSts.Value
            OUT_VeSRMR_e_LimitationMd_Value: accessed-variable=VeSRMR_e_LimitationMd.Value
            OUT_VeSRMR_b_MtrMdVldtnFltErr_Value: accessed-variable=VeSRMR_b_MtrMdVldtnFltErr.Value
            OUT_VeSRMR_v_VehSpd_Value: accessed-variable=VeSRMR_v_VehSpd.Value
            OUT_VeSRMR_b_VehSpdFA_Value: accessed-variable=VeSRMR_b_VehSpdFA.Value
            OUT_VeSRMR_e_PPawl_Request_Value: accessed-variable=VeSRMR_e_PPawl_Request.Value
            OUT_VeSRMR_M_RegenBrkAxTorqCapFrnt_Value: accessed-variable=VeSRMR_M_RegenBrkAxTorqCapFrnt.Value
            OUT_VeSRMR_M_RegenBrkAxTorqCapRear_Value: accessed-variable=VeSRMR_M_RegenBrkAxTorqCapRear.Value
